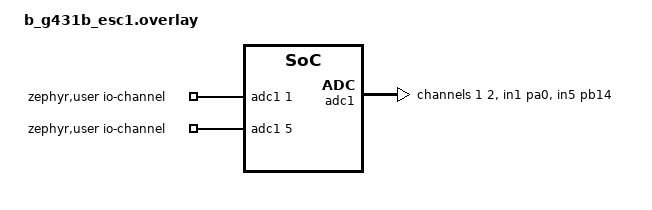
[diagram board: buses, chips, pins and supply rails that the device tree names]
/*
 * Copyright (c) 2024 Alexander Kozhinov <ak.alexander.kozhinov@gmail.com>
 * SPDX-License-Identifier: Apache-2.0
 */

/ {
	zephyr,user {
		/* adjust channel number according to pinmux in board.dts */
		io-channels = <&adc1 1>, <&adc1 5>;
	};
};

&adc1 {
	dmas = <&dmamux1 0 5 (
		STM32_DMA_MODE_CYCLIC |
		STM32_DMA_PERIPH_RX |
		STM32_DMA_MEM_16BITS |
		STM32_DMA_PERIPH_16BITS
		)>;
	dma-names = "dmamux";

	pinctrl-0 = <&adc1_in1_pa0 &adc1_in5_pb14>;
	#address-cells = <1>;
	#size-cells = <0>;

	channel@1 {
		reg = <1>;
		zephyr,gain = "ADC_GAIN_1";
		zephyr,reference = "ADC_REF_INTERNAL";
		zephyr,acquisition-time = <ADC_ACQ_TIME_DEFAULT>;
		zephyr,resolution = <12>;
	};

	channel@5 {
		reg = <2>;
		zephyr,gain = "ADC_GAIN_1";
		zephyr,reference = "ADC_REF_INTERNAL";
		zephyr,acquisition-time = <ADC_ACQ_TIME_DEFAULT>;
		zephyr,resolution = <12>;
	};
};

&dma1 {
	status = "okay";
};

&dmamux1 {
	status = "okay";
};
